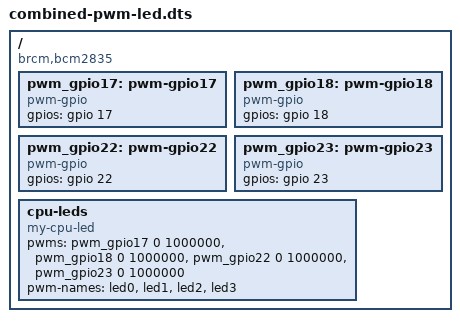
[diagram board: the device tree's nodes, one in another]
/dts-v1/;
/plugin/;

/ {
    compatible = "brcm,bcm2835";

    fragment@0 {
        target-path = "/";
        __overlay__ {

            pwm_gpio17: pwm-gpio17 {
                compatible = "pwm-gpio";
                gpios = <&gpio 17 0>;
                #pwm-cells = <2>;
                status = "okay";
            };
            pwm_gpio18: pwm-gpio18 {
                compatible = "pwm-gpio";
                gpios = <&gpio 18 0>;
                #pwm-cells = <2>;
                status = "okay";
            };
            pwm_gpio22: pwm-gpio22 {
                compatible = "pwm-gpio";
                gpios = <&gpio 22 0>;
                #pwm-cells = <2>;
                status = "okay";
            };
            pwm_gpio23: pwm-gpio23 {
                compatible = "pwm-gpio";
                gpios = <&gpio 23 0>;
                #pwm-cells = <2>;
                status = "okay";
            };

            cpu-leds {
                compatible = "my-cpu-led";
                status = "okay";

                pwms = <&pwm_gpio17 0 1000000>,
                       <&pwm_gpio18 0 1000000>,
                       <&pwm_gpio22 0 1000000>,
                       <&pwm_gpio23 0 1000000>;

                pwm-names = "led0", "led1", "led2", "led3";
            };

        };
    };
};
